AUTOSAR XML (schema 314)
package /ComponentType
  internal behavior Sa_MtrVel2_InternalBehavior: component=Sa_MtrVel2
    timing event MtrVel2_InitEvent: start-on-event=MtrVel2_Init, period=0
    timing event TMT_MtrVel2_Per1: start-on-event=MtrVel2_Per1, period=0.002
    timing event TMT_MtrVel2_Per2: start-on-event=MtrVel2_Per2, period=0.004
    port-api-options:
      enable-take-address=false, indirect-api=false, port=AsstAssemPol
      enable-take-address=false, indirect-api=false, port=CumMtrPosMRF
      enable-take-address=false, indirect-api=false, port=HandWheelVel
      enable-take-address=false, indirect-api=false, port=MRFMotorVel
      enable-take-address=false, indirect-api=false, port=MtrVel2_Per1_CP0
      enable-take-address=false, indirect-api=false, port=MtrVel2_Per2_CP0
      enable-take-address=false, indirect-api=false, port=NxtrDiagMgr
      enable-take-address=false, indirect-api=false, port=SysCDiagHandWheelVel
      enable-take-address=false, indirect-api=false, port=SysCDiagMtrVelMRF
    runnable MtrVel2_Init
      data read access READ_CumMtrPosMRF_Deg_f32: data-element=CumMtrPosMRF.Deg_f32
    runnable MtrVel2_Per1
      data read access READ_AsstAssemPol_Cnt_s08: data-element=AsstAssemPol.Cnt_s08
      data read access READ_CumMtrPosMRF_Deg_f32: data-element=CumMtrPosMRF.Deg_f32
      data write access WRITE_SysCDiagHandWheelVel_HwRadpS_f32: data-element=SysCDiagHandWheelVel.HwRadpS_f32
      data write access WRITE_SysCDiagMtrVelMRF_MtrRadpS_f32: data-element=SysCDiagMtrVelMRF.MtrRadpS_f32
      sync call SC_MtrVel2_Per1_CP0_CheckpointReached: operation=MtrVel2_Per1_CP0.CheckpointReached, timeout=0
    runnable MtrVel2_Per2
      data read access READ_HandWheelVel_HwRadpS_f32: data-element=HandWheelVel.HwRadpS_f32
      data read access READ_MRFMotorVel_MtrRadpS_f32: data-element=MRFMotorVel.MtrRadpS_f32
      sync call SC_MtrVel2_Per2_CP0_CheckpointReached: operation=MtrVel2_Per2_CP0.CheckpointReached, timeout=0
      sync call SC_NxtrDiagMgr_SetNTCStatus: operation=NxtrDiagMgr.SetNTCStatus, timeout=0
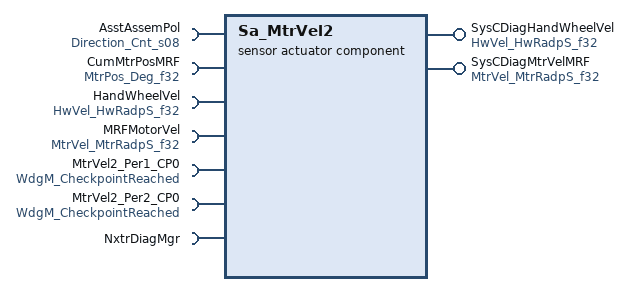
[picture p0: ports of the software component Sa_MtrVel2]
  sensor actuator software component type Sa_MtrVel2
    provide port SysCDiagHandWheelVel: unqueued-sender-com-spec{data-element=HwRadpS_f32, can-invalidate=false, init-value=D_FLOATZERO_ULS_F32}, provided-interface=HwVel_HwRadpS_f32
    provide port SysCDiagMtrVelMRF: unqueued-sender-com-spec{data-element=MtrRadpS_f32, can-invalidate=false, init-value=D_FLOATZERO_ULS_F32}, provided-interface=MtrVel_MtrRadpS_f32
    7 x require port:
      AsstAssemPol: unqueued-receiver-com-spec{data-element=Cnt_s08, init-value=D_ZERO_CNT_S8}, required-interface=Direction_Cnt_s08
      CumMtrPosMRF: unqueued-receiver-com-spec{data-element=Deg_f32, init-value=D_FLOATZERO_ULS_F32}, required-interface=MtrPos_Deg_f32
      HandWheelVel: unqueued-receiver-com-spec{data-element=HwRadpS_f32, init-value=D_FLOATZERO_ULS_F32}, required-interface=HwVel_HwRadpS_f32
      MRFMotorVel: unqueued-receiver-com-spec{data-element=MtrRadpS_f32, init-value=D_FLOATZERO_ULS_F32}, required-interface=MtrVel_MtrRadpS_f32
      MtrVel2_Per1_CP0: client-com-spec=CheckpointReached, required-interface=WdgM_CheckpointReached
      MtrVel2_Per2_CP0: client-com-spec=CheckpointReached, required-interface=WdgM_CheckpointReached
      NxtrDiagMgr: required-com-specs=[GetNTCActive, GetNTCFailed, GetNTCStatus, SetNTCStatus], required-interface=NxtrDiagMgr
  swc implementation Sa_MtrVel2_Implementation: behavior=Sa_MtrVel2_InternalBehavior
    code-descriptors:
      code Code: type=SRC
